# sir_me21 register map
Registers are read-only, no defined reset value unless marked. A register's access mark holds for its fields unless they carry their own. Offsets are from the block's base; lines under a group give offsets from that group; [hi:lo] are bit positions; {n}, {i} and the like mark numbered series; 'fields as' and 'values as' point back to an identical list; <NAME> marks a mode.

## Memory map
0x40000400 SIR size 0x400 — System Initialization Registers.

## SIR — System Initialization Registers.
Base 0x40000400
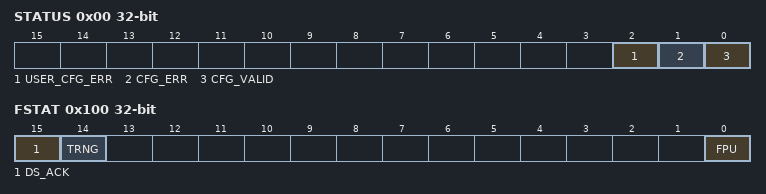
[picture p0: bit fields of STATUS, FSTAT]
0x00 STATUS — System Initialization Status Register.
  [2] USER_CFG_ERR — User Configuration Error Flag.
  [1] CFG_ERR — Configuration Error Flag.
  [0] CFG_VALID — Configuration Valid Flag.
0x04 ADDR — Read-only field set by the SIB block if a CRC error occurs during the read of the OTP memory. Contains the failing address in OTP memory (when CRCERR equals 1).
  [31:0] ADDR
0x100 FSTAT — Function Status Register.
  [15] DS_ACK — DeepSleep Acknowledge.
  [14] TRNG — TRNG Function.
  [0] FPU — FPU Function.
0x104 SFSTAT — Security Function Status Register.
  [0] SECFUNC0 — Secure Function 0 Status.
